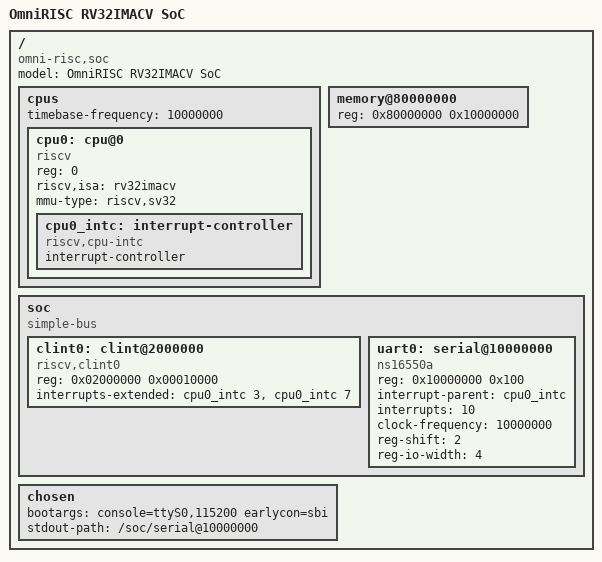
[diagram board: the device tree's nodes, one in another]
/dts-v1/;

/ {
    #address-cells = <1>;
    #size-cells = <1>;
    model = "OmniRISC RV32IMACV SoC";
    compatible = "omni-risc,soc";

    cpus {
        #address-cells = <1>;
        #size-cells = <0>;
        timebase-frequency = <10000000>;

        cpu0: cpu@0 {
            device_type = "cpu";
            reg = <0>;
            status = "okay";
            compatible = "riscv";
            riscv,isa = "rv32imacv"; // Added A and C
            mmu-type = "riscv,sv32";

            cpu0_intc: interrupt-controller {
                #interrupt-cells = <1>;
                interrupt-controller;
                compatible = "riscv,cpu-intc";
            };
        };
    };

    memory@80000000 {
        device_type = "memory";
        reg = <0x80000000 0x10000000>;
    };

    soc {
        #address-cells = <1>;
        #size-cells = <1>;
        compatible = "simple-bus";
        ranges;

        clint0: clint@2000000 {
            compatible = "riscv,clint0";
            reg = <0x02000000 0x00010000>;
            interrupts-extended = <&cpu0_intc 3 &cpu0_intc 7>;
        };

        uart0: serial@10000000 {
            compatible = "ns16550a";
            reg = <0x10000000 0x100>;
            interrupt-parent = <&cpu0_intc>;
            interrupts = <10>;
            clock-frequency = <10000000>;
            reg-shift = <2>;
            reg-io-width = <4>;
            status = "okay";
        };
    };

    chosen {
        bootargs = "console=ttyS0,115200 earlycon=sbi";
        stdout-path = "/soc/serial@10000000";
    };
};
